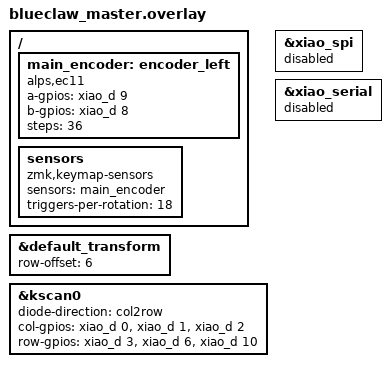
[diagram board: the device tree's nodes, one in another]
/*
 * Copyright (c) 2020 Pete Johanson
 *
 * SPDX-License-Identifier: MIT
 */

#include "blueclaw.dtsi"



&default_transform { // The matrix transform for this board is 6 columns over because the left half is 6 columns wide according to the matrix.
    row-offset = <6>;
};

&kscan0 {
    diode-direction = "col2row";
    col-gpios
            = <&xiao_d 0 GPIO_ACTIVE_HIGH>
            , <&xiao_d 1 GPIO_ACTIVE_HIGH>
            , <&xiao_d 2 GPIO_ACTIVE_HIGH>
            ;

    row-gpios
            = <&xiao_d 3 (GPIO_ACTIVE_HIGH | GPIO_PULL_DOWN)>
            , <&xiao_d 6 (GPIO_ACTIVE_HIGH | GPIO_PULL_DOWN)>
            , <&xiao_d 10 (GPIO_ACTIVE_HIGH | GPIO_PULL_DOWN)>
            ;
};

/{
    main_encoder: encoder_left {
        compatible = "alps,ec11";
        a-gpios = <&xiao_d 9  (GPIO_ACTIVE_HIGH | GPIO_PULL_UP)>;
        b-gpios = <&xiao_d 8  (GPIO_ACTIVE_HIGH | GPIO_PULL_UP)>;
        steps = <36>;
        status = "okay";
    };

    sensors: sensors {
        compatible = "zmk,keymap-sensors";
        sensors = <&main_encoder>;
        triggers-per-rotation = <18>;
    };

};

&xiao_spi { status = "disabled";};
&xiao_serial { status = "disabled";};
